# cslr_aif register map
Vendor: Texas Instruments
Registers are 32-bit, access per field, reset 0x0 unless marked. A register's access mark holds for its fields unless they carry their own. Offsets are as the file gives them; [hi:lo] are bit positions; {n}, {i} and the like mark numbered series; 'fields as' and 'values as' point back to an identical list.

## AIF (part 3 of 5) — High-speed interface for BTS antenna data
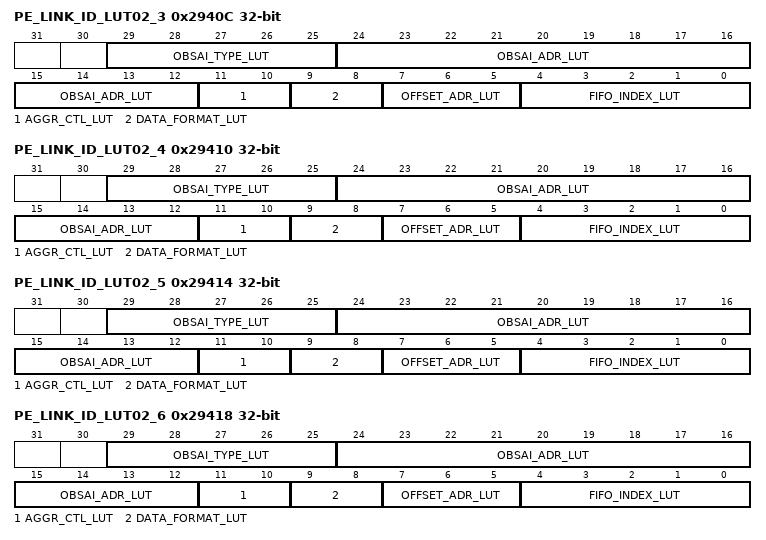
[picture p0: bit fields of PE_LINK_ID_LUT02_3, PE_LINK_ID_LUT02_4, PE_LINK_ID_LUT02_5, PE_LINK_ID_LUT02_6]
0x2940C PE_LINK_ID_LUT02_3 — Protocol Encoder Identity LUT part 0{PE_LINK_ID_LUT02}
  [29:25] OBSAI_TYPE_LUT rw — Bits [4:0]: OBSAI type, fixed per antenna carrier (circuit switched only)
  [24:12] OBSAI_ADR_LUT rw — Bits [12:0]: OBSAI address, fixed per antenna carrier (circuit switched only)
  [11:10] AGGR_CTL_LUT rw — Bits [1:0]: Aggregation control bits (assuming Tx_Rule passes)
    0=NOP (NOP (Ag still pulls from FIFO, but does not use read PE data bytes)); 1=INSERT; 2=ADD15_16 (Add 15/16bit); 3=ADD7_8 (Add 7/8bit)
  [9:8] DATA_FORMAT_LUT rw — Bits [1:0]: Internal Data format:
    0=DL_FMT (DL Format(only legal with burst of 4)); 1=UL_FMT (UL RSA Format(only legal for burst of 8)); 2=PIC_FMT (PIC MAI); 3=GEN_FMT (Generic Format)
  [7:5] OFFSET_ADR_LUT rw — Bits [2:0]: Circularly offsets reads from circuit switched RAM by n*4 chips. 8 chip orientated UL data disregard the LSB assuming it is zero. This offset is used to correct RAM alignment between streams different MOD32 offsets with one another. Allows chained DMA's to be more regular.
  [4:0] FIFO_INDEX_LUT rw — Bite [4:0]: pktsw FIFO Index[4:0]. Used to address fifo corresponding to this link.
0x29410 PE_LINK_ID_LUT02_4 — Protocol Encoder Identity LUT part 0{PE_LINK_ID_LUT02}
  fields as PE_LINK_ID_LUT02_3
0x29414 PE_LINK_ID_LUT02_5 — Protocol Encoder Identity LUT part 0{PE_LINK_ID_LUT02}
  fields as PE_LINK_ID_LUT02_3
0x29418 PE_LINK_ID_LUT02_6 — Protocol Encoder Identity LUT part 0{PE_LINK_ID_LUT02}
  fields as PE_LINK_ID_LUT02_3
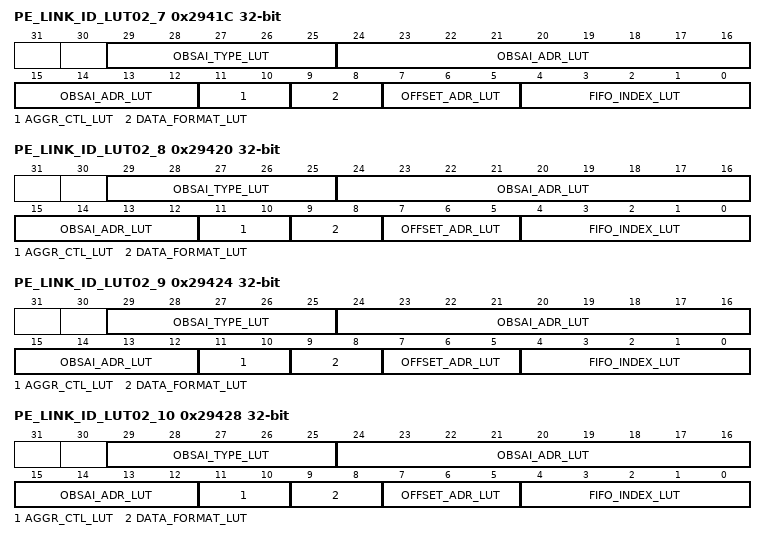
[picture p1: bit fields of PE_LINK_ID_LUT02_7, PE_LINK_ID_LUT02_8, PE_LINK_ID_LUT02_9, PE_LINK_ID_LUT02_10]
0x2941C PE_LINK_ID_LUT02_7 — Protocol Encoder Identity LUT part 0{PE_LINK_ID_LUT02}
  fields as PE_LINK_ID_LUT02_3
0x29420 PE_LINK_ID_LUT02_8 — Protocol Encoder Identity LUT part 0{PE_LINK_ID_LUT02}
  fields as PE_LINK_ID_LUT02_3
0x29424 PE_LINK_ID_LUT02_9 — Protocol Encoder Identity LUT part 0{PE_LINK_ID_LUT02}
  fields as PE_LINK_ID_LUT02_3
0x29428 PE_LINK_ID_LUT02_10 — Protocol Encoder Identity LUT part 0{PE_LINK_ID_LUT02}
  fields as PE_LINK_ID_LUT02_3
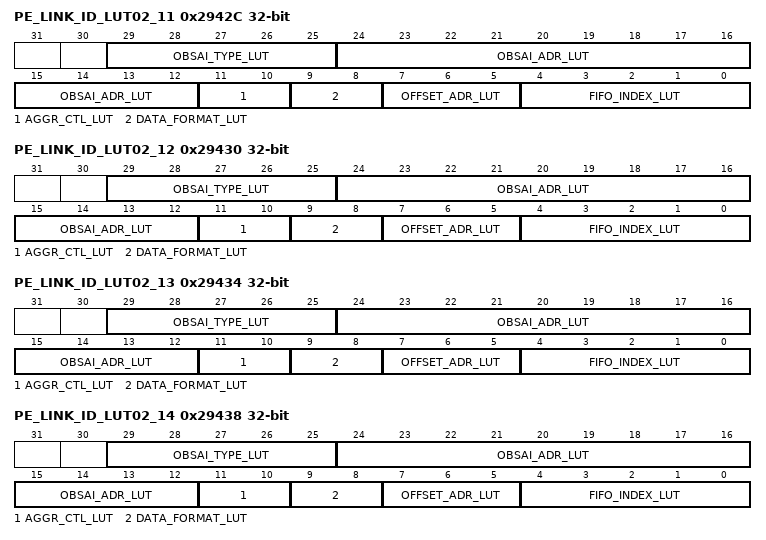
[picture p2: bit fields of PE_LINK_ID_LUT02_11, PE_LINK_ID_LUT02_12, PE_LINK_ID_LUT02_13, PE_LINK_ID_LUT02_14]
0x2942C PE_LINK_ID_LUT02_11 — Protocol Encoder Identity LUT part 0{PE_LINK_ID_LUT02}
  fields as PE_LINK_ID_LUT02_3
0x29430 PE_LINK_ID_LUT02_12 — Protocol Encoder Identity LUT part 0{PE_LINK_ID_LUT02}
  fields as PE_LINK_ID_LUT02_3
0x29434 PE_LINK_ID_LUT02_13 — Protocol Encoder Identity LUT part 0{PE_LINK_ID_LUT02}
  fields as PE_LINK_ID_LUT02_3
0x29438 PE_LINK_ID_LUT02_14 — Protocol Encoder Identity LUT part 0{PE_LINK_ID_LUT02}
  fields as PE_LINK_ID_LUT02_3
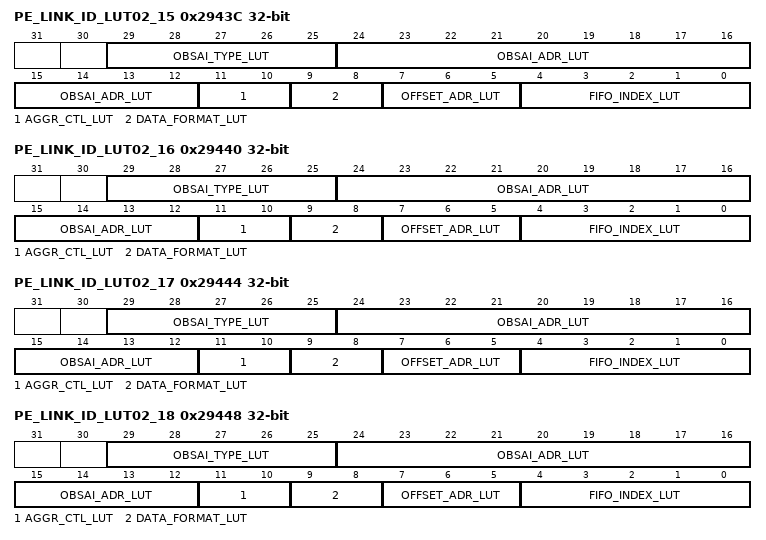
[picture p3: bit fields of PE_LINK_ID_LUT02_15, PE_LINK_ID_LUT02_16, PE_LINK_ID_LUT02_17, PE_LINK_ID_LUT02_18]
0x2943C PE_LINK_ID_LUT02_15 — Protocol Encoder Identity LUT part 0{PE_LINK_ID_LUT02}
  fields as PE_LINK_ID_LUT02_3
0x29440 PE_LINK_ID_LUT02_16 — Protocol Encoder Identity LUT part 0{PE_LINK_ID_LUT02}
  fields as PE_LINK_ID_LUT02_3
0x29444 PE_LINK_ID_LUT02_17 — Protocol Encoder Identity LUT part 0{PE_LINK_ID_LUT02}
  fields as PE_LINK_ID_LUT02_3
0x29448 PE_LINK_ID_LUT02_18 — Protocol Encoder Identity LUT part 0{PE_LINK_ID_LUT02}
  fields as PE_LINK_ID_LUT02_3
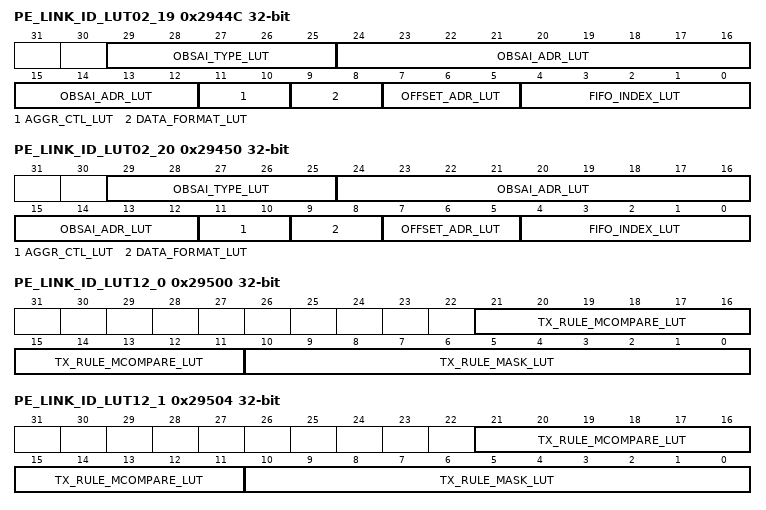
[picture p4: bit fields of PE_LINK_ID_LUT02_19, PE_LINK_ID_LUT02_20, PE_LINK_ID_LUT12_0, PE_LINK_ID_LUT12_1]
0x2944C PE_LINK_ID_LUT02_19 — Protocol Encoder Identity LUT part 0{PE_LINK_ID_LUT02}
  fields as PE_LINK_ID_LUT02_3
0x29450 PE_LINK_ID_LUT02_20 — Protocol Encoder Identity LUT part 0{PE_LINK_ID_LUT02}
  fields as PE_LINK_ID_LUT02_3
0x29500 PE_LINK_ID_LUT12_0 — Protocol Encoder Identity LUT part 1{PE_LINK_ID_LUT12}
  [21:11] TX_RULE_MCOMPARE_LUT rw — Bits [10:0]: Transmission rule compare bits. Field is bitwise XNOR with current counter value. Enabled results (see tx_rule_mask) are reduction AND giving a pass/fail of the transmission rule.
  [10:0] TX_RULE_MASK_LUT rw — Bits [10:0]: transmission rule mask. Indicates which counter bits should be compared. 0: indicates bit automatically passes compare 1: indicates counter bit should be compared with tx_rule_compare field.
0x29504 PE_LINK_ID_LUT12_1 — Protocol Encoder Identity LUT part 1{PE_LINK_ID_LUT12}
  fields as PE_LINK_ID_LUT12_0
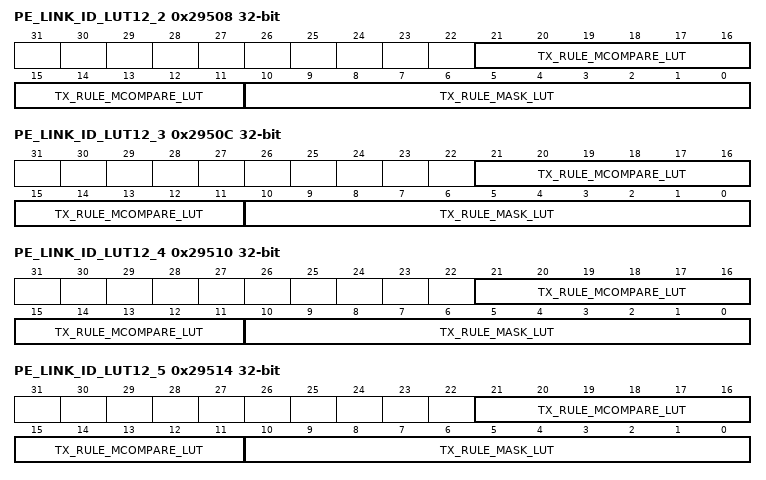
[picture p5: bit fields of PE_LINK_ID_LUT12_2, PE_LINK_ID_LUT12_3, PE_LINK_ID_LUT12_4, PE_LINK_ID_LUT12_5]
0x29508 PE_LINK_ID_LUT12_2 — Protocol Encoder Identity LUT part 1{PE_LINK_ID_LUT12}
  fields as PE_LINK_ID_LUT12_0
0x2950C PE_LINK_ID_LUT12_3 — Protocol Encoder Identity LUT part 1{PE_LINK_ID_LUT12}
  fields as PE_LINK_ID_LUT12_0
0x29510 PE_LINK_ID_LUT12_4 — Protocol Encoder Identity LUT part 1{PE_LINK_ID_LUT12}
  fields as PE_LINK_ID_LUT12_0
0x29514 PE_LINK_ID_LUT12_5 — Protocol Encoder Identity LUT part 1{PE_LINK_ID_LUT12}
  fields as PE_LINK_ID_LUT12_0
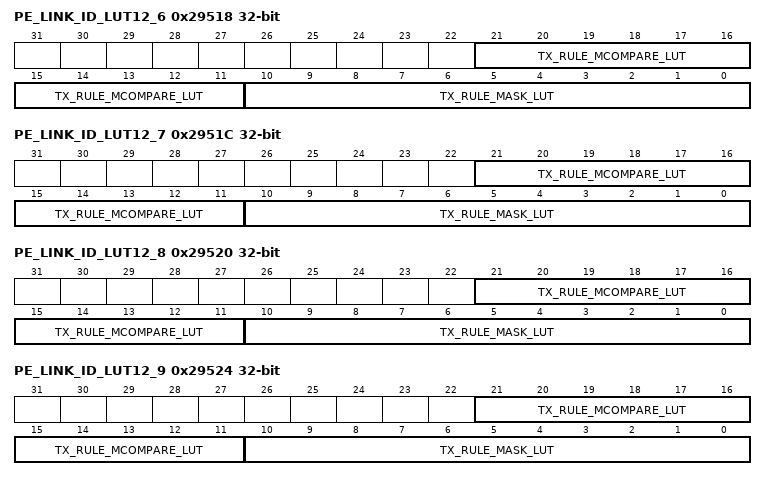
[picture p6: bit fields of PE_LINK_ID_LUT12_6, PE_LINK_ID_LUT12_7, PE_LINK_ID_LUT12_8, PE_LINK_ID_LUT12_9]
0x29518 PE_LINK_ID_LUT12_6 — Protocol Encoder Identity LUT part 1{PE_LINK_ID_LUT12}
  fields as PE_LINK_ID_LUT12_0
0x2951C PE_LINK_ID_LUT12_7 — Protocol Encoder Identity LUT part 1{PE_LINK_ID_LUT12}
  fields as PE_LINK_ID_LUT12_0
0x29520 PE_LINK_ID_LUT12_8 — Protocol Encoder Identity LUT part 1{PE_LINK_ID_LUT12}
  fields as PE_LINK_ID_LUT12_0
0x29524 PE_LINK_ID_LUT12_9 — Protocol Encoder Identity LUT part 1{PE_LINK_ID_LUT12}
  fields as PE_LINK_ID_LUT12_0
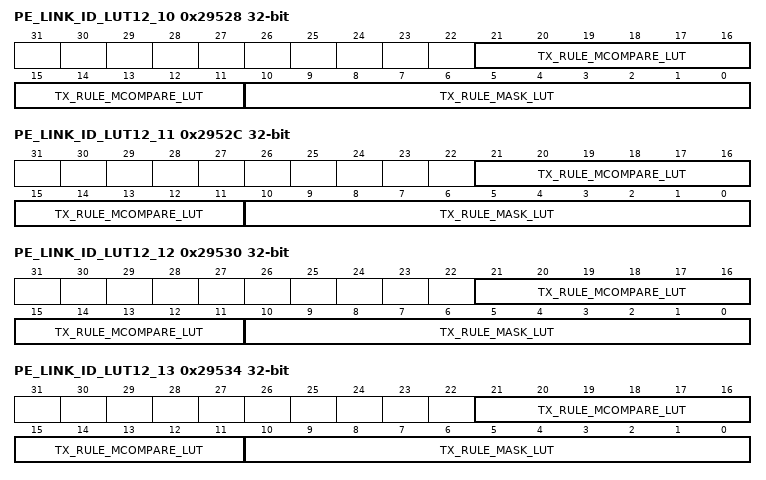
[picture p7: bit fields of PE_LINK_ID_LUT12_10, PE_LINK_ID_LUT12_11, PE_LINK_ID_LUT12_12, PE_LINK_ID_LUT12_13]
0x29528 PE_LINK_ID_LUT12_10 — Protocol Encoder Identity LUT part 1{PE_LINK_ID_LUT12}
  fields as PE_LINK_ID_LUT12_0
0x2952C PE_LINK_ID_LUT12_11 — Protocol Encoder Identity LUT part 1{PE_LINK_ID_LUT12}
  fields as PE_LINK_ID_LUT12_0
0x29530 PE_LINK_ID_LUT12_12 — Protocol Encoder Identity LUT part 1{PE_LINK_ID_LUT12}
  fields as PE_LINK_ID_LUT12_0
0x29534 PE_LINK_ID_LUT12_13 — Protocol Encoder Identity LUT part 1{PE_LINK_ID_LUT12}
  fields as PE_LINK_ID_LUT12_0
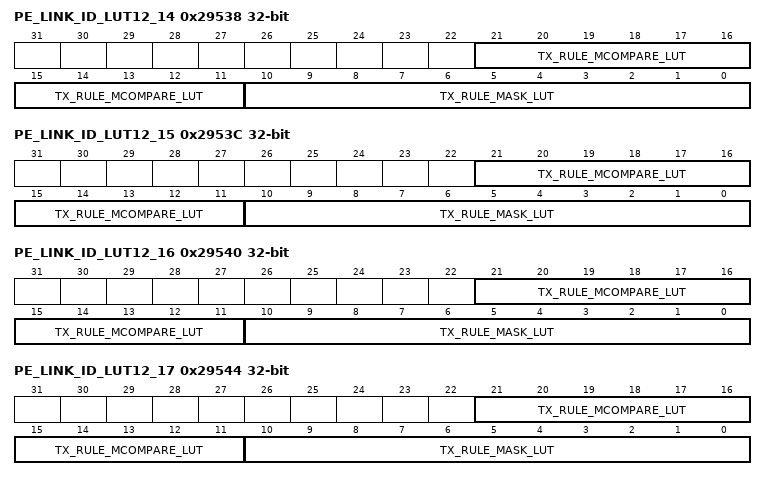
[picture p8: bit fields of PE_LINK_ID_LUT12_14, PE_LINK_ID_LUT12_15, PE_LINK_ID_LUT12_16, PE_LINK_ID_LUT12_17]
0x29538 PE_LINK_ID_LUT12_14 — Protocol Encoder Identity LUT part 1{PE_LINK_ID_LUT12}
  fields as PE_LINK_ID_LUT12_0
0x2953C PE_LINK_ID_LUT12_15 — Protocol Encoder Identity LUT part 1{PE_LINK_ID_LUT12}
  fields as PE_LINK_ID_LUT12_0
0x29540 PE_LINK_ID_LUT12_16 — Protocol Encoder Identity LUT part 1{PE_LINK_ID_LUT12}
  fields as PE_LINK_ID_LUT12_0
0x29544 PE_LINK_ID_LUT12_17 — Protocol Encoder Identity LUT part 1{PE_LINK_ID_LUT12}
  fields as PE_LINK_ID_LUT12_0
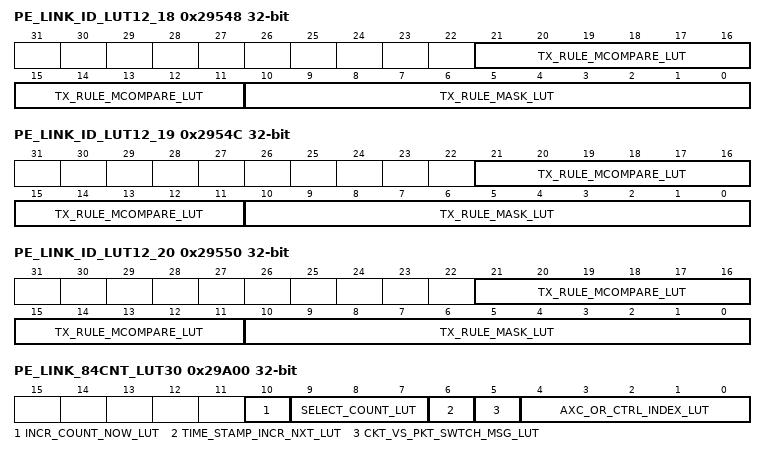
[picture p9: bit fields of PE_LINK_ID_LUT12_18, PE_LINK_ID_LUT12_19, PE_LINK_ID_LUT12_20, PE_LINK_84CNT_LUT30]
0x29548 PE_LINK_ID_LUT12_18 — Protocol Encoder Identity LUT part 1{PE_LINK_ID_LUT12}
  fields as PE_LINK_ID_LUT12_0
0x2954C PE_LINK_ID_LUT12_19 — Protocol Encoder Identity LUT part 1{PE_LINK_ID_LUT12}
  fields as PE_LINK_ID_LUT12_0
0x29550 PE_LINK_ID_LUT12_20 — Protocol Encoder Identity LUT part 1{PE_LINK_ID_LUT12}
  fields as PE_LINK_ID_LUT12_0
0x29A00 PE_LINK_84CNT_LUT30 — Protocol Encoder Link 84 Count LUT{PE_LINK_84CNT_LUT3}
  [10] INCR_COUNT_NOW_LUT rw — controls counter to increment, Incremented value is used for next operation (current operation uses current counter value)
    1=ICNR; 0=NO_INCR
  [9:7] SELECT_COUNT_LUT rw — Bits [2:0]: "0"-"3": Selects 4x Control Slot Counters or "4": 1x Data Slot Counter for Increment and for use with transmission rule
    {v}=CTRL{v} (v=0..3); 4=DATA
  [6] TIME_STAMP_INCR_NXT_LUT rw — Controls Time Stamp to increment, Incremented value is used for next message
  [5] CKT_VS_PKT_SWTCH_MSG_LUT rw — 0: circuit switched data
    0=PACKET; 1=CIRCUIT
  [4:0] AXC_OR_CTRL_INDEX_LUT rw — Bits [4:0]: Index for accessing the identity LUT.
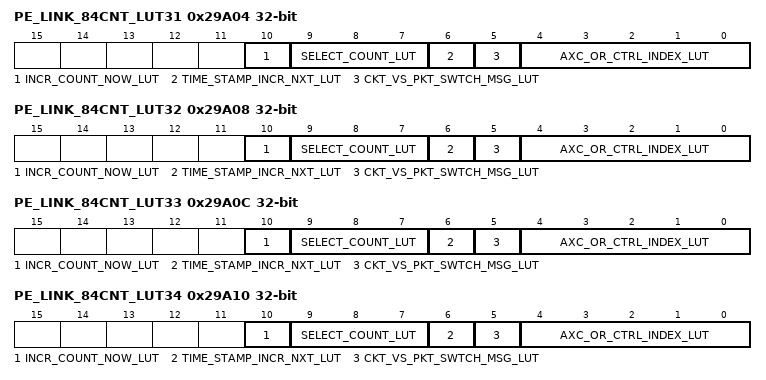
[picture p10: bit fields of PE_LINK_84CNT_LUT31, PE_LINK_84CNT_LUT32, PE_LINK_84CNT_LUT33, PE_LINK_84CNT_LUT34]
0x29A04 PE_LINK_84CNT_LUT31 — Protocol Encoder Link 84 Count LUT{PE_LINK_84CNT_LUT3}
  fields as PE_LINK_84CNT_LUT30
0x29A08 PE_LINK_84CNT_LUT32 — Protocol Encoder Link 84 Count LUT{PE_LINK_84CNT_LUT3}
  fields as PE_LINK_84CNT_LUT30
0x29A0C PE_LINK_84CNT_LUT33 — Protocol Encoder Link 84 Count LUT{PE_LINK_84CNT_LUT3}
  fields as PE_LINK_84CNT_LUT30
0x29A10 PE_LINK_84CNT_LUT34 — Protocol Encoder Link 84 Count LUT{PE_LINK_84CNT_LUT3}
  fields as PE_LINK_84CNT_LUT30
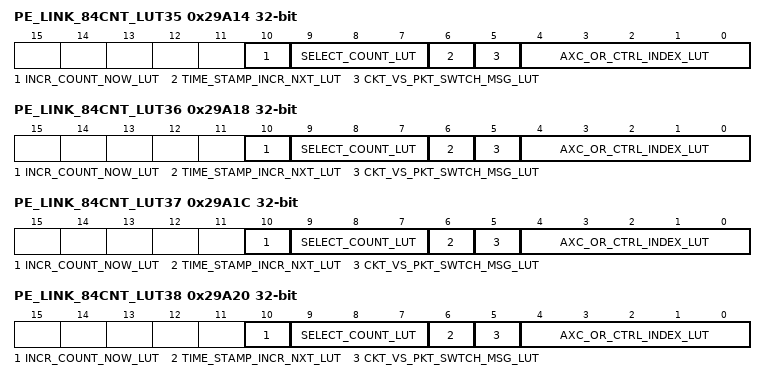
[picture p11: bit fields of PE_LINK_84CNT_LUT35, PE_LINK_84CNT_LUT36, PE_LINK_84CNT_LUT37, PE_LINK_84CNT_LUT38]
0x29A14 PE_LINK_84CNT_LUT35 — Protocol Encoder Link 84 Count LUT{PE_LINK_84CNT_LUT3}
  fields as PE_LINK_84CNT_LUT30
0x29A18 PE_LINK_84CNT_LUT36 — Protocol Encoder Link 84 Count LUT{PE_LINK_84CNT_LUT3}
  fields as PE_LINK_84CNT_LUT30
0x29A1C PE_LINK_84CNT_LUT37 — Protocol Encoder Link 84 Count LUT{PE_LINK_84CNT_LUT3}
  fields as PE_LINK_84CNT_LUT30
0x29A20 PE_LINK_84CNT_LUT38 — Protocol Encoder Link 84 Count LUT{PE_LINK_84CNT_LUT3}
  fields as PE_LINK_84CNT_LUT30
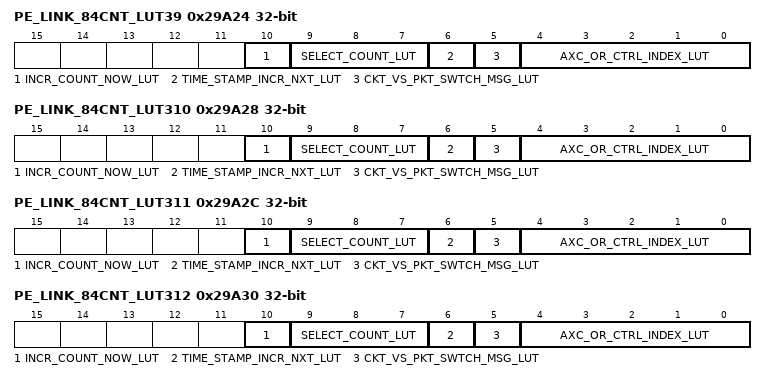
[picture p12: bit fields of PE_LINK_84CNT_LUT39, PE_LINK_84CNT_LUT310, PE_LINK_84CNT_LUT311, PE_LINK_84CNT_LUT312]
0x29A24 PE_LINK_84CNT_LUT39 — Protocol Encoder Link 84 Count LUT{PE_LINK_84CNT_LUT3}
  fields as PE_LINK_84CNT_LUT30
0x29A28 PE_LINK_84CNT_LUT310 — Protocol Encoder Link 84 Count LUT{PE_LINK_84CNT_LUT3}
  fields as PE_LINK_84CNT_LUT30
0x29A2C PE_LINK_84CNT_LUT311 — Protocol Encoder Link 84 Count LUT{PE_LINK_84CNT_LUT3}
  fields as PE_LINK_84CNT_LUT30
0x29A30 PE_LINK_84CNT_LUT312 — Protocol Encoder Link 84 Count LUT{PE_LINK_84CNT_LUT3}
  fields as PE_LINK_84CNT_LUT30
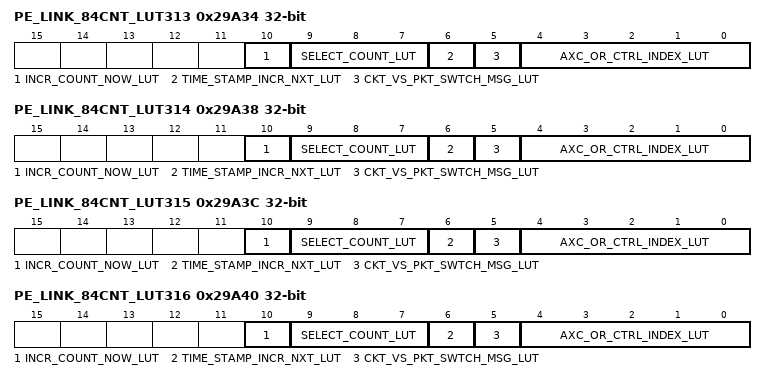
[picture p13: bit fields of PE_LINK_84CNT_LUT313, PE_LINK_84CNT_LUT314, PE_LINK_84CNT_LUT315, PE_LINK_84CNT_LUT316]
0x29A34 PE_LINK_84CNT_LUT313 — Protocol Encoder Link 84 Count LUT{PE_LINK_84CNT_LUT3}
  fields as PE_LINK_84CNT_LUT30
0x29A38 PE_LINK_84CNT_LUT314 — Protocol Encoder Link 84 Count LUT{PE_LINK_84CNT_LUT3}
  fields as PE_LINK_84CNT_LUT30
0x29A3C PE_LINK_84CNT_LUT315 — Protocol Encoder Link 84 Count LUT{PE_LINK_84CNT_LUT3}
  fields as PE_LINK_84CNT_LUT30
0x29A40 PE_LINK_84CNT_LUT316 — Protocol Encoder Link 84 Count LUT{PE_LINK_84CNT_LUT3}
  fields as PE_LINK_84CNT_LUT30
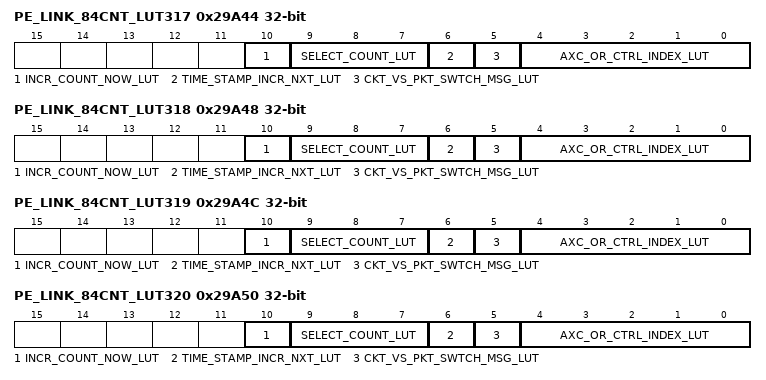
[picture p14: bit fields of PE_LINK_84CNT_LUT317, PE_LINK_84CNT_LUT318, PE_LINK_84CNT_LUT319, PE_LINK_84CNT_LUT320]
0x29A44 PE_LINK_84CNT_LUT317 — Protocol Encoder Link 84 Count LUT{PE_LINK_84CNT_LUT3}
  fields as PE_LINK_84CNT_LUT30
0x29A48 PE_LINK_84CNT_LUT318 — Protocol Encoder Link 84 Count LUT{PE_LINK_84CNT_LUT3}
  fields as PE_LINK_84CNT_LUT30
0x29A4C PE_LINK_84CNT_LUT319 — Protocol Encoder Link 84 Count LUT{PE_LINK_84CNT_LUT3}
  fields as PE_LINK_84CNT_LUT30
0x29A50 PE_LINK_84CNT_LUT320 — Protocol Encoder Link 84 Count LUT{PE_LINK_84CNT_LUT3}
  fields as PE_LINK_84CNT_LUT30
0x29A54 PE_LINK_84CNT_LUT321 — Protocol Encoder Link 84 Count LUT{PE_LINK_84CNT_LUT3}
  fields as PE_LINK_84CNT_LUT30
0x29A58 PE_LINK_84CNT_LUT322 — Protocol Encoder Link 84 Count LUT{PE_LINK_84CNT_LUT3}
  fields as PE_LINK_84CNT_LUT30
0x29A5C PE_LINK_84CNT_LUT323 — Protocol Encoder Link 84 Count LUT{PE_LINK_84CNT_LUT3}
  fields as PE_LINK_84CNT_LUT30
0x29A60 PE_LINK_84CNT_LUT324 — Protocol Encoder Link 84 Count LUT{PE_LINK_84CNT_LUT3}
  fields as PE_LINK_84CNT_LUT30
0x29A64 PE_LINK_84CNT_LUT325 — Protocol Encoder Link 84 Count LUT{PE_LINK_84CNT_LUT3}
  fields as PE_LINK_84CNT_LUT30
0x29A68 PE_LINK_84CNT_LUT326 — Protocol Encoder Link 84 Count LUT{PE_LINK_84CNT_LUT3}
  fields as PE_LINK_84CNT_LUT30
0x29A6C PE_LINK_84CNT_LUT327 — Protocol Encoder Link 84 Count LUT{PE_LINK_84CNT_LUT3}
  fields as PE_LINK_84CNT_LUT30
0x29A70 PE_LINK_84CNT_LUT328 — Protocol Encoder Link 84 Count LUT{PE_LINK_84CNT_LUT3}
  fields as PE_LINK_84CNT_LUT30
0x29A74 PE_LINK_84CNT_LUT329 — Protocol Encoder Link 84 Count LUT{PE_LINK_84CNT_LUT3}
  fields as PE_LINK_84CNT_LUT30
0x29A78 PE_LINK_84CNT_LUT330 — Protocol Encoder Link 84 Count LUT{PE_LINK_84CNT_LUT3}
  fields as PE_LINK_84CNT_LUT30
0x29A7C PE_LINK_84CNT_LUT331 — Protocol Encoder Link 84 Count LUT{PE_LINK_84CNT_LUT3}
  fields as PE_LINK_84CNT_LUT30
0x29A80 PE_LINK_84CNT_LUT332 — Protocol Encoder Link 84 Count LUT{PE_LINK_84CNT_LUT3}
  fields as PE_LINK_84CNT_LUT30
0x29A84 PE_LINK_84CNT_LUT333 — Protocol Encoder Link 84 Count LUT{PE_LINK_84CNT_LUT3}
  fields as PE_LINK_84CNT_LUT30
0x29A88 PE_LINK_84CNT_LUT334 — Protocol Encoder Link 84 Count LUT{PE_LINK_84CNT_LUT3}
  fields as PE_LINK_84CNT_LUT30
0x29A8C PE_LINK_84CNT_LUT335 — Protocol Encoder Link 84 Count LUT{PE_LINK_84CNT_LUT3}
  fields as PE_LINK_84CNT_LUT30
0x29A90 PE_LINK_84CNT_LUT336 — Protocol Encoder Link 84 Count LUT{PE_LINK_84CNT_LUT3}
  fields as PE_LINK_84CNT_LUT30
0x29A94 PE_LINK_84CNT_LUT337 — Protocol Encoder Link 84 Count LUT{PE_LINK_84CNT_LUT3}
  fields as PE_LINK_84CNT_LUT30
0x29A98 PE_LINK_84CNT_LUT338 — Protocol Encoder Link 84 Count LUT{PE_LINK_84CNT_LUT3}
  fields as PE_LINK_84CNT_LUT30
0x29A9C PE_LINK_84CNT_LUT339 — Protocol Encoder Link 84 Count LUT{PE_LINK_84CNT_LUT3}
  fields as PE_LINK_84CNT_LUT30
0x29AA0 PE_LINK_84CNT_LUT340 — Protocol Encoder Link 84 Count LUT{PE_LINK_84CNT_LUT3}
  fields as PE_LINK_84CNT_LUT30
0x29AA4 PE_LINK_84CNT_LUT341 — Protocol Encoder Link 84 Count LUT{PE_LINK_84CNT_LUT3}
  fields as PE_LINK_84CNT_LUT30
0x29AA8 PE_LINK_84CNT_LUT342 — Protocol Encoder Link 84 Count LUT{PE_LINK_84CNT_LUT3}
  fields as PE_LINK_84CNT_LUT30
0x29AAC PE_LINK_84CNT_LUT343 — Protocol Encoder Link 84 Count LUT{PE_LINK_84CNT_LUT3}
  fields as PE_LINK_84CNT_LUT30
0x29AB0 PE_LINK_84CNT_LUT344 — Protocol Encoder Link 84 Count LUT{PE_LINK_84CNT_LUT3}
  fields as PE_LINK_84CNT_LUT30
0x29AB4 PE_LINK_84CNT_LUT345 — Protocol Encoder Link 84 Count LUT{PE_LINK_84CNT_LUT3}
  fields as PE_LINK_84CNT_LUT30
0x29AB8 PE_LINK_84CNT_LUT346 — Protocol Encoder Link 84 Count LUT{PE_LINK_84CNT_LUT3}
  fields as PE_LINK_84CNT_LUT30
0x29ABC PE_LINK_84CNT_LUT347 — Protocol Encoder Link 84 Count LUT{PE_LINK_84CNT_LUT3}
  fields as PE_LINK_84CNT_LUT30
0x29AC0 PE_LINK_84CNT_LUT348 — Protocol Encoder Link 84 Count LUT{PE_LINK_84CNT_LUT3}
  fields as PE_LINK_84CNT_LUT30
0x29AC4 PE_LINK_84CNT_LUT349 — Protocol Encoder Link 84 Count LUT{PE_LINK_84CNT_LUT3}
  fields as PE_LINK_84CNT_LUT30
0x29AC8 PE_LINK_84CNT_LUT350 — Protocol Encoder Link 84 Count LUT{PE_LINK_84CNT_LUT3}
  fields as PE_LINK_84CNT_LUT30
0x29ACC PE_LINK_84CNT_LUT351 — Protocol Encoder Link 84 Count LUT{PE_LINK_84CNT_LUT3}
  fields as PE_LINK_84CNT_LUT30
0x29AD0 PE_LINK_84CNT_LUT352 — Protocol Encoder Link 84 Count LUT{PE_LINK_84CNT_LUT3}
  fields as PE_LINK_84CNT_LUT30
0x29AD4 PE_LINK_84CNT_LUT353 — Protocol Encoder Link 84 Count LUT{PE_LINK_84CNT_LUT3}
  fields as PE_LINK_84CNT_LUT30
0x29AD8 PE_LINK_84CNT_LUT354 — Protocol Encoder Link 84 Count LUT{PE_LINK_84CNT_LUT3}
  fields as PE_LINK_84CNT_LUT30
0x29ADC PE_LINK_84CNT_LUT355 — Protocol Encoder Link 84 Count LUT{PE_LINK_84CNT_LUT3}
  fields as PE_LINK_84CNT_LUT30
0x29AE0 PE_LINK_84CNT_LUT356 — Protocol Encoder Link 84 Count LUT{PE_LINK_84CNT_LUT3}
  fields as PE_LINK_84CNT_LUT30
0x29AE4 PE_LINK_84CNT_LUT357 — Protocol Encoder Link 84 Count LUT{PE_LINK_84CNT_LUT3}
  fields as PE_LINK_84CNT_LUT30
0x29AE8 PE_LINK_84CNT_LUT358 — Protocol Encoder Link 84 Count LUT{PE_LINK_84CNT_LUT3}
  fields as PE_LINK_84CNT_LUT30
0x29AEC PE_LINK_84CNT_LUT359 — Protocol Encoder Link 84 Count LUT{PE_LINK_84CNT_LUT3}
  fields as PE_LINK_84CNT_LUT30
0x29AF0 PE_LINK_84CNT_LUT360 — Protocol Encoder Link 84 Count LUT{PE_LINK_84CNT_LUT3}
  fields as PE_LINK_84CNT_LUT30
0x29AF4 PE_LINK_84CNT_LUT361 — Protocol Encoder Link 84 Count LUT{PE_LINK_84CNT_LUT3}
  fields as PE_LINK_84CNT_LUT30
0x29AF8 PE_LINK_84CNT_LUT362 — Protocol Encoder Link 84 Count LUT{PE_LINK_84CNT_LUT3}
  fields as PE_LINK_84CNT_LUT30
0x29AFC PE_LINK_84CNT_LUT363 — Protocol Encoder Link 84 Count LUT{PE_LINK_84CNT_LUT3}
  fields as PE_LINK_84CNT_LUT30
0x29B00 PE_LINK_84CNT_LUT364 — Protocol Encoder Link 84 Count LUT{PE_LINK_84CNT_LUT3}
  fields as PE_LINK_84CNT_LUT30
0x29B04 PE_LINK_84CNT_LUT365 — Protocol Encoder Link 84 Count LUT{PE_LINK_84CNT_LUT3}
  fields as PE_LINK_84CNT_LUT30
0x29B08 PE_LINK_84CNT_LUT366 — Protocol Encoder Link 84 Count LUT{PE_LINK_84CNT_LUT3}
  fields as PE_LINK_84CNT_LUT30
0x29B0C PE_LINK_84CNT_LUT367 — Protocol Encoder Link 84 Count LUT{PE_LINK_84CNT_LUT3}
  fields as PE_LINK_84CNT_LUT30
0x29B10 PE_LINK_84CNT_LUT368 — Protocol Encoder Link 84 Count LUT{PE_LINK_84CNT_LUT3}
  fields as PE_LINK_84CNT_LUT30
0x29B14 PE_LINK_84CNT_LUT369 — Protocol Encoder Link 84 Count LUT{PE_LINK_84CNT_LUT3}
  fields as PE_LINK_84CNT_LUT30
0x29B18 PE_LINK_84CNT_LUT370 — Protocol Encoder Link 84 Count LUT{PE_LINK_84CNT_LUT3}
  fields as PE_LINK_84CNT_LUT30
0x29B1C PE_LINK_84CNT_LUT371 — Protocol Encoder Link 84 Count LUT{PE_LINK_84CNT_LUT3}
  fields as PE_LINK_84CNT_LUT30
0x29B20 PE_LINK_84CNT_LUT372 — Protocol Encoder Link 84 Count LUT{PE_LINK_84CNT_LUT3}
  fields as PE_LINK_84CNT_LUT30
0x29B24 PE_LINK_84CNT_LUT373 — Protocol Encoder Link 84 Count LUT{PE_LINK_84CNT_LUT3}
  fields as PE_LINK_84CNT_LUT30
0x29B28 PE_LINK_84CNT_LUT374 — Protocol Encoder Link 84 Count LUT{PE_LINK_84CNT_LUT3}
  fields as PE_LINK_84CNT_LUT30
0x29B2C PE_LINK_84CNT_LUT375 — Protocol Encoder Link 84 Count LUT{PE_LINK_84CNT_LUT3}
  fields as PE_LINK_84CNT_LUT30
0x29B30 PE_LINK_84CNT_LUT376 — Protocol Encoder Link 84 Count LUT{PE_LINK_84CNT_LUT3}
  fields as PE_LINK_84CNT_LUT30
0x29B34 PE_LINK_84CNT_LUT377 — Protocol Encoder Link 84 Count LUT{PE_LINK_84CNT_LUT3}
  fields as PE_LINK_84CNT_LUT30
0x29B38 PE_LINK_84CNT_LUT378 — Protocol Encoder Link 84 Count LUT{PE_LINK_84CNT_LUT3}
  fields as PE_LINK_84CNT_LUT30
0x29B3C PE_LINK_84CNT_LUT379 — Protocol Encoder Link 84 Count LUT{PE_LINK_84CNT_LUT3}
  fields as PE_LINK_84CNT_LUT30
0x29B40 PE_LINK_84CNT_LUT380 — Protocol Encoder Link 84 Count LUT{PE_LINK_84CNT_LUT3}
  fields as PE_LINK_84CNT_LUT30
0x29B44 PE_LINK_84CNT_LUT381 — Protocol Encoder Link 84 Count LUT{PE_LINK_84CNT_LUT3}
  fields as PE_LINK_84CNT_LUT30
0x29B48 PE_LINK_84CNT_LUT382 — Protocol Encoder Link 84 Count LUT{PE_LINK_84CNT_LUT3}
  fields as PE_LINK_84CNT_LUT30
0x29B4C PE_LINK_84CNT_LUT383 — Protocol Encoder Link 84 Count LUT{PE_LINK_84CNT_LUT3}
  fields as PE_LINK_84CNT_LUT30
0x29C00 PE_LINK_ID_LUT03_0 — Protocol Encoder Identity LUT part 0{PE_LINK_ID_LUT03}
  fields as PE_LINK_ID_LUT02_3
0x29C04 PE_LINK_ID_LUT03_1 — Protocol Encoder Identity LUT part 0{PE_LINK_ID_LUT03}
  fields as PE_LINK_ID_LUT02_3
0x29C08 PE_LINK_ID_LUT03_2 — Protocol Encoder Identity LUT part 0{PE_LINK_ID_LUT03}
  fields as PE_LINK_ID_LUT02_3
0x29C0C PE_LINK_ID_LUT03_3 — Protocol Encoder Identity LUT part 0{PE_LINK_ID_LUT03}
  fields as PE_LINK_ID_LUT02_3
0x29C10 PE_LINK_ID_LUT03_4 — Protocol Encoder Identity LUT part 0{PE_LINK_ID_LUT03}
  fields as PE_LINK_ID_LUT02_3
0x29C14 PE_LINK_ID_LUT03_5 — Protocol Encoder Identity LUT part 0{PE_LINK_ID_LUT03}
  fields as PE_LINK_ID_LUT02_3
0x29C18 PE_LINK_ID_LUT03_6 — Protocol Encoder Identity LUT part 0{PE_LINK_ID_LUT03}
  fields as PE_LINK_ID_LUT02_3
0x29C1C PE_LINK_ID_LUT03_7 — Protocol Encoder Identity LUT part 0{PE_LINK_ID_LUT03}
  fields as PE_LINK_ID_LUT02_3
0x29C20 PE_LINK_ID_LUT03_8 — Protocol Encoder Identity LUT part 0{PE_LINK_ID_LUT03}
  fields as PE_LINK_ID_LUT02_3
0x29C24 PE_LINK_ID_LUT03_9 — Protocol Encoder Identity LUT part 0{PE_LINK_ID_LUT03}
  fields as PE_LINK_ID_LUT02_3
0x29C28 PE_LINK_ID_LUT03_10 — Protocol Encoder Identity LUT part 0{PE_LINK_ID_LUT03}
  fields as PE_LINK_ID_LUT02_3
0x29C2C PE_LINK_ID_LUT03_11 — Protocol Encoder Identity LUT part 0{PE_LINK_ID_LUT03}
  fields as PE_LINK_ID_LUT02_3
0x29C30 PE_LINK_ID_LUT03_12 — Protocol Encoder Identity LUT part 0{PE_LINK_ID_LUT03}
  fields as PE_LINK_ID_LUT02_3
0x29C34 PE_LINK_ID_LUT03_13 — Protocol Encoder Identity LUT part 0{PE_LINK_ID_LUT03}
  fields as PE_LINK_ID_LUT02_3
0x29C38 PE_LINK_ID_LUT03_14 — Protocol Encoder Identity LUT part 0{PE_LINK_ID_LUT03}
  fields as PE_LINK_ID_LUT02_3
0x29C3C PE_LINK_ID_LUT03_15 — Protocol Encoder Identity LUT part 0{PE_LINK_ID_LUT03}
  fields as PE_LINK_ID_LUT02_3
0x29C40 PE_LINK_ID_LUT03_16 — Protocol Encoder Identity LUT part 0{PE_LINK_ID_LUT03}
  fields as PE_LINK_ID_LUT02_3
0x29C44 PE_LINK_ID_LUT03_17 — Protocol Encoder Identity LUT part 0{PE_LINK_ID_LUT03}
  fields as PE_LINK_ID_LUT02_3
0x29C48 PE_LINK_ID_LUT03_18 — Protocol Encoder Identity LUT part 0{PE_LINK_ID_LUT03}
  fields as PE_LINK_ID_LUT02_3
0x29C4C PE_LINK_ID_LUT03_19 — Protocol Encoder Identity LUT part 0{PE_LINK_ID_LUT03}
  fields as PE_LINK_ID_LUT02_3
0x29C50 PE_LINK_ID_LUT03_20 — Protocol Encoder Identity LUT part 0{PE_LINK_ID_LUT03}
  fields as PE_LINK_ID_LUT02_3
0x29D00 PE_LINK_ID_LUT13_0 — Protocol Encoder Identity LUT part 1{PE_LINK_ID_LUT13}
  fields as PE_LINK_ID_LUT12_0
0x29D04 PE_LINK_ID_LUT13_1 — Protocol Encoder Identity LUT part 1{PE_LINK_ID_LUT13}
  fields as PE_LINK_ID_LUT12_0
0x29D08 PE_LINK_ID_LUT13_2 — Protocol Encoder Identity LUT part 1{PE_LINK_ID_LUT13}
  fields as PE_LINK_ID_LUT12_0
0x29D0C PE_LINK_ID_LUT13_3 — Protocol Encoder Identity LUT part 1{PE_LINK_ID_LUT13}
  fields as PE_LINK_ID_LUT12_0
0x29D10 PE_LINK_ID_LUT13_4 — Protocol Encoder Identity LUT part 1{PE_LINK_ID_LUT13}
  fields as PE_LINK_ID_LUT12_0
0x29D14 PE_LINK_ID_LUT13_5 — Protocol Encoder Identity LUT part 1{PE_LINK_ID_LUT13}
  fields as PE_LINK_ID_LUT12_0
0x29D18 PE_LINK_ID_LUT13_6 — Protocol Encoder Identity LUT part 1{PE_LINK_ID_LUT13}
  fields as PE_LINK_ID_LUT12_0
0x29D1C PE_LINK_ID_LUT13_7 — Protocol Encoder Identity LUT part 1{PE_LINK_ID_LUT13}
  fields as PE_LINK_ID_LUT12_0
0x29D20 PE_LINK_ID_LUT13_8 — Protocol Encoder Identity LUT part 1{PE_LINK_ID_LUT13}
  fields as PE_LINK_ID_LUT12_0
0x29D24 PE_LINK_ID_LUT13_9 — Protocol Encoder Identity LUT part 1{PE_LINK_ID_LUT13}
  fields as PE_LINK_ID_LUT12_0
0x29D28 PE_LINK_ID_LUT13_10 — Protocol Encoder Identity LUT part 1{PE_LINK_ID_LUT13}
  fields as PE_LINK_ID_LUT12_0
0x29D2C PE_LINK_ID_LUT13_11 — Protocol Encoder Identity LUT part 1{PE_LINK_ID_LUT13}
  fields as PE_LINK_ID_LUT12_0
0x29D30 PE_LINK_ID_LUT13_12 — Protocol Encoder Identity LUT part 1{PE_LINK_ID_LUT13}
  fields as PE_LINK_ID_LUT12_0
0x29D34 PE_LINK_ID_LUT13_13 — Protocol Encoder Identity LUT part 1{PE_LINK_ID_LUT13}
  fields as PE_LINK_ID_LUT12_0
0x29D38 PE_LINK_ID_LUT13_14 — Protocol Encoder Identity LUT part 1{PE_LINK_ID_LUT13}
  fields as PE_LINK_ID_LUT12_0
0x29D3C PE_LINK_ID_LUT13_15 — Protocol Encoder Identity LUT part 1{PE_LINK_ID_LUT13}
  fields as PE_LINK_ID_LUT12_0
0x29D40 PE_LINK_ID_LUT13_16 — Protocol Encoder Identity LUT part 1{PE_LINK_ID_LUT13}
  fields as PE_LINK_ID_LUT12_0
0x29D44 PE_LINK_ID_LUT13_17 — Protocol Encoder Identity LUT part 1{PE_LINK_ID_LUT13}
  fields as PE_LINK_ID_LUT12_0
0x29D48 PE_LINK_ID_LUT13_18 — Protocol Encoder Identity LUT part 1{PE_LINK_ID_LUT13}
  fields as PE_LINK_ID_LUT12_0
0x29D4C PE_LINK_ID_LUT13_19 — Protocol Encoder Identity LUT part 1{PE_LINK_ID_LUT13}
  fields as PE_LINK_ID_LUT12_0
0x29D50 PE_LINK_ID_LUT13_20 — Protocol Encoder Identity LUT part 1{PE_LINK_ID_LUT13}
  fields as PE_LINK_ID_LUT12_0
0x2A200 PE_LINK_84CNT_LUT40 — Protocol Encoder Link 84 Count LUT{PE_LINK_84CNT_LUT4}
  fields as PE_LINK_84CNT_LUT30
0x2A204 PE_LINK_84CNT_LUT41 — Protocol Encoder Link 84 Count LUT{PE_LINK_84CNT_LUT4}
  fields as PE_LINK_84CNT_LUT30
0x2A208 PE_LINK_84CNT_LUT42 — Protocol Encoder Link 84 Count LUT{PE_LINK_84CNT_LUT4}
  fields as PE_LINK_84CNT_LUT30
0x2A20C PE_LINK_84CNT_LUT43 — Protocol Encoder Link 84 Count LUT{PE_LINK_84CNT_LUT4}
  fields as PE_LINK_84CNT_LUT30
0x2A210 PE_LINK_84CNT_LUT44 — Protocol Encoder Link 84 Count LUT{PE_LINK_84CNT_LUT4}
  fields as PE_LINK_84CNT_LUT30
0x2A214 PE_LINK_84CNT_LUT45 — Protocol Encoder Link 84 Count LUT{PE_LINK_84CNT_LUT4}
  fields as PE_LINK_84CNT_LUT30
0x2A218 PE_LINK_84CNT_LUT46 — Protocol Encoder Link 84 Count LUT{PE_LINK_84CNT_LUT4}
  fields as PE_LINK_84CNT_LUT30
0x2A21C PE_LINK_84CNT_LUT47 — Protocol Encoder Link 84 Count LUT{PE_LINK_84CNT_LUT4}
  fields as PE_LINK_84CNT_LUT30
0x2A220 PE_LINK_84CNT_LUT48 — Protocol Encoder Link 84 Count LUT{PE_LINK_84CNT_LUT4}
  fields as PE_LINK_84CNT_LUT30
0x2A224 PE_LINK_84CNT_LUT49 — Protocol Encoder Link 84 Count LUT{PE_LINK_84CNT_LUT4}
  fields as PE_LINK_84CNT_LUT30
0x2A228 PE_LINK_84CNT_LUT410 — Protocol Encoder Link 84 Count LUT{PE_LINK_84CNT_LUT4}
  fields as PE_LINK_84CNT_LUT30
0x2A22C PE_LINK_84CNT_LUT411 — Protocol Encoder Link 84 Count LUT{PE_LINK_84CNT_LUT4}
  fields as PE_LINK_84CNT_LUT30
0x2A230 PE_LINK_84CNT_LUT412 — Protocol Encoder Link 84 Count LUT{PE_LINK_84CNT_LUT4}
  fields as PE_LINK_84CNT_LUT30
0x2A234 PE_LINK_84CNT_LUT413 — Protocol Encoder Link 84 Count LUT{PE_LINK_84CNT_LUT4}
  fields as PE_LINK_84CNT_LUT30
0x2A238 PE_LINK_84CNT_LUT414 — Protocol Encoder Link 84 Count LUT{PE_LINK_84CNT_LUT4}
  fields as PE_LINK_84CNT_LUT30
0x2A23C PE_LINK_84CNT_LUT415 — Protocol Encoder Link 84 Count LUT{PE_LINK_84CNT_LUT4}
  fields as PE_LINK_84CNT_LUT30
0x2A240 PE_LINK_84CNT_LUT416 — Protocol Encoder Link 84 Count LUT{PE_LINK_84CNT_LUT4}
  fields as PE_LINK_84CNT_LUT30
0x2A244 PE_LINK_84CNT_LUT417 — Protocol Encoder Link 84 Count LUT{PE_LINK_84CNT_LUT4}
  fields as PE_LINK_84CNT_LUT30
0x2A248 PE_LINK_84CNT_LUT418 — Protocol Encoder Link 84 Count LUT{PE_LINK_84CNT_LUT4}
  fields as PE_LINK_84CNT_LUT30
0x2A24C PE_LINK_84CNT_LUT419 — Protocol Encoder Link 84 Count LUT{PE_LINK_84CNT_LUT4}
  fields as PE_LINK_84CNT_LUT30
0x2A250 PE_LINK_84CNT_LUT420 — Protocol Encoder Link 84 Count LUT{PE_LINK_84CNT_LUT4}
  fields as PE_LINK_84CNT_LUT30
0x2A254 PE_LINK_84CNT_LUT421 — Protocol Encoder Link 84 Count LUT{PE_LINK_84CNT_LUT4}
  fields as PE_LINK_84CNT_LUT30
0x2A258 PE_LINK_84CNT_LUT422 — Protocol Encoder Link 84 Count LUT{PE_LINK_84CNT_LUT4}
  fields as PE_LINK_84CNT_LUT30
0x2A25C PE_LINK_84CNT_LUT423 — Protocol Encoder Link 84 Count LUT{PE_LINK_84CNT_LUT4}
  fields as PE_LINK_84CNT_LUT30
0x2A260 PE_LINK_84CNT_LUT424 — Protocol Encoder Link 84 Count LUT{PE_LINK_84CNT_LUT4}
  fields as PE_LINK_84CNT_LUT30
0x2A264 PE_LINK_84CNT_LUT425 — Protocol Encoder Link 84 Count LUT{PE_LINK_84CNT_LUT4}
  fields as PE_LINK_84CNT_LUT30
0x2A268 PE_LINK_84CNT_LUT426 — Protocol Encoder Link 84 Count LUT{PE_LINK_84CNT_LUT4}
  fields as PE_LINK_84CNT_LUT30
0x2A26C PE_LINK_84CNT_LUT427 — Protocol Encoder Link 84 Count LUT{PE_LINK_84CNT_LUT4}
  fields as PE_LINK_84CNT_LUT30
0x2A270 PE_LINK_84CNT_LUT428 — Protocol Encoder Link 84 Count LUT{PE_LINK_84CNT_LUT4}
  fields as PE_LINK_84CNT_LUT30
0x2A274 PE_LINK_84CNT_LUT429 — Protocol Encoder Link 84 Count LUT{PE_LINK_84CNT_LUT4}
  fields as PE_LINK_84CNT_LUT30
0x2A278 PE_LINK_84CNT_LUT430 — Protocol Encoder Link 84 Count LUT{PE_LINK_84CNT_LUT4}
  fields as PE_LINK_84CNT_LUT30
0x2A27C PE_LINK_84CNT_LUT431 — Protocol Encoder Link 84 Count LUT{PE_LINK_84CNT_LUT4}
  fields as PE_LINK_84CNT_LUT30
0x2A280 PE_LINK_84CNT_LUT432 — Protocol Encoder Link 84 Count LUT{PE_LINK_84CNT_LUT4}
  fields as PE_LINK_84CNT_LUT30
0x2A284 PE_LINK_84CNT_LUT433 — Protocol Encoder Link 84 Count LUT{PE_LINK_84CNT_LUT4}
  fields as PE_LINK_84CNT_LUT30
0x2A288 PE_LINK_84CNT_LUT434 — Protocol Encoder Link 84 Count LUT{PE_LINK_84CNT_LUT4}
  fields as PE_LINK_84CNT_LUT30
0x2A28C PE_LINK_84CNT_LUT435 — Protocol Encoder Link 84 Count LUT{PE_LINK_84CNT_LUT4}
  fields as PE_LINK_84CNT_LUT30
0x2A290 PE_LINK_84CNT_LUT436 — Protocol Encoder Link 84 Count LUT{PE_LINK_84CNT_LUT4}
  fields as PE_LINK_84CNT_LUT30
0x2A294 PE_LINK_84CNT_LUT437 — Protocol Encoder Link 84 Count LUT{PE_LINK_84CNT_LUT4}
  fields as PE_LINK_84CNT_LUT30
0x2A298 PE_LINK_84CNT_LUT438 — Protocol Encoder Link 84 Count LUT{PE_LINK_84CNT_LUT4}
  fields as PE_LINK_84CNT_LUT30
0x2A29C PE_LINK_84CNT_LUT439 — Protocol Encoder Link 84 Count LUT{PE_LINK_84CNT_LUT4}
  fields as PE_LINK_84CNT_LUT30
0x2A2A0 PE_LINK_84CNT_LUT440 — Protocol Encoder Link 84 Count LUT{PE_LINK_84CNT_LUT4}
  fields as PE_LINK_84CNT_LUT30
0x2A2A4 PE_LINK_84CNT_LUT441 — Protocol Encoder Link 84 Count LUT{PE_LINK_84CNT_LUT4}
  fields as PE_LINK_84CNT_LUT30
0x2A2A8 PE_LINK_84CNT_LUT442 — Protocol Encoder Link 84 Count LUT{PE_LINK_84CNT_LUT4}
  fields as PE_LINK_84CNT_LUT30
0x2A2AC PE_LINK_84CNT_LUT443 — Protocol Encoder Link 84 Count LUT{PE_LINK_84CNT_LUT4}
  fields as PE_LINK_84CNT_LUT30
0x2A2B0 PE_LINK_84CNT_LUT444 — Protocol Encoder Link 84 Count LUT{PE_LINK_84CNT_LUT4}
  fields as PE_LINK_84CNT_LUT30
0x2A2B4 PE_LINK_84CNT_LUT445 — Protocol Encoder Link 84 Count LUT{PE_LINK_84CNT_LUT4}
  fields as PE_LINK_84CNT_LUT30
0x2A2B8 PE_LINK_84CNT_LUT446 — Protocol Encoder Link 84 Count LUT{PE_LINK_84CNT_LUT4}
  fields as PE_LINK_84CNT_LUT30
0x2A2BC PE_LINK_84CNT_LUT447 — Protocol Encoder Link 84 Count LUT{PE_LINK_84CNT_LUT4}
  fields as PE_LINK_84CNT_LUT30
0x2A2C0 PE_LINK_84CNT_LUT448 — Protocol Encoder Link 84 Count LUT{PE_LINK_84CNT_LUT4}
  fields as PE_LINK_84CNT_LUT30
0x2A2C4 PE_LINK_84CNT_LUT449 — Protocol Encoder Link 84 Count LUT{PE_LINK_84CNT_LUT4}
  fields as PE_LINK_84CNT_LUT30
0x2A2C8 PE_LINK_84CNT_LUT450 — Protocol Encoder Link 84 Count LUT{PE_LINK_84CNT_LUT4}
  fields as PE_LINK_84CNT_LUT30
0x2A2CC PE_LINK_84CNT_LUT451 — Protocol Encoder Link 84 Count LUT{PE_LINK_84CNT_LUT4}
  fields as PE_LINK_84CNT_LUT30
0x2A2D0 PE_LINK_84CNT_LUT452 — Protocol Encoder Link 84 Count LUT{PE_LINK_84CNT_LUT4}
  fields as PE_LINK_84CNT_LUT30
0x2A2D4 PE_LINK_84CNT_LUT453 — Protocol Encoder Link 84 Count LUT{PE_LINK_84CNT_LUT4}
  fields as PE_LINK_84CNT_LUT30
0x2A2D8 PE_LINK_84CNT_LUT454 — Protocol Encoder Link 84 Count LUT{PE_LINK_84CNT_LUT4}
  fields as PE_LINK_84CNT_LUT30
0x2A2DC PE_LINK_84CNT_LUT455 — Protocol Encoder Link 84 Count LUT{PE_LINK_84CNT_LUT4}
  fields as PE_LINK_84CNT_LUT30
0x2A2E0 PE_LINK_84CNT_LUT456 — Protocol Encoder Link 84 Count LUT{PE_LINK_84CNT_LUT4}
  fields as PE_LINK_84CNT_LUT30
0x2A2E4 PE_LINK_84CNT_LUT457 — Protocol Encoder Link 84 Count LUT{PE_LINK_84CNT_LUT4}
  fields as PE_LINK_84CNT_LUT30
0x2A2E8 PE_LINK_84CNT_LUT458 — Protocol Encoder Link 84 Count LUT{PE_LINK_84CNT_LUT4}
  fields as PE_LINK_84CNT_LUT30
0x2A2EC PE_LINK_84CNT_LUT459 — Protocol Encoder Link 84 Count LUT{PE_LINK_84CNT_LUT4}
  fields as PE_LINK_84CNT_LUT30
0x2A2F0 PE_LINK_84CNT_LUT460 — Protocol Encoder Link 84 Count LUT{PE_LINK_84CNT_LUT4}
  fields as PE_LINK_84CNT_LUT30
0x2A2F4 PE_LINK_84CNT_LUT461 — Protocol Encoder Link 84 Count LUT{PE_LINK_84CNT_LUT4}
  fields as PE_LINK_84CNT_LUT30
0x2A2F8 PE_LINK_84CNT_LUT462 — Protocol Encoder Link 84 Count LUT{PE_LINK_84CNT_LUT4}
  fields as PE_LINK_84CNT_LUT30
0x2A2FC PE_LINK_84CNT_LUT463 — Protocol Encoder Link 84 Count LUT{PE_LINK_84CNT_LUT4}
  fields as PE_LINK_84CNT_LUT30
0x2A300 PE_LINK_84CNT_LUT464 — Protocol Encoder Link 84 Count LUT{PE_LINK_84CNT_LUT4}
  fields as PE_LINK_84CNT_LUT30
0x2A304 PE_LINK_84CNT_LUT465 — Protocol Encoder Link 84 Count LUT{PE_LINK_84CNT_LUT4}
  fields as PE_LINK_84CNT_LUT30
0x2A308 PE_LINK_84CNT_LUT466 — Protocol Encoder Link 84 Count LUT{PE_LINK_84CNT_LUT4}
  fields as PE_LINK_84CNT_LUT30
0x2A30C PE_LINK_84CNT_LUT467 — Protocol Encoder Link 84 Count LUT{PE_LINK_84CNT_LUT4}
  fields as PE_LINK_84CNT_LUT30
0x2A310 PE_LINK_84CNT_LUT468 — Protocol Encoder Link 84 Count LUT{PE_LINK_84CNT_LUT4}
  fields as PE_LINK_84CNT_LUT30
0x2A314 PE_LINK_84CNT_LUT469 — Protocol Encoder Link 84 Count LUT{PE_LINK_84CNT_LUT4}
  fields as PE_LINK_84CNT_LUT30
0x2A318 PE_LINK_84CNT_LUT470 — Protocol Encoder Link 84 Count LUT{PE_LINK_84CNT_LUT4}
  fields as PE_LINK_84CNT_LUT30
0x2A31C PE_LINK_84CNT_LUT471 — Protocol Encoder Link 84 Count LUT{PE_LINK_84CNT_LUT4}
  fields as PE_LINK_84CNT_LUT30
0x2A320 PE_LINK_84CNT_LUT472 — Protocol Encoder Link 84 Count LUT{PE_LINK_84CNT_LUT4}
  fields as PE_LINK_84CNT_LUT30
0x2A324 PE_LINK_84CNT_LUT473 — Protocol Encoder Link 84 Count LUT{PE_LINK_84CNT_LUT4}
  fields as PE_LINK_84CNT_LUT30
0x2A328 PE_LINK_84CNT_LUT474 — Protocol Encoder Link 84 Count LUT{PE_LINK_84CNT_LUT4}
  fields as PE_LINK_84CNT_LUT30
0x2A32C PE_LINK_84CNT_LUT475 — Protocol Encoder Link 84 Count LUT{PE_LINK_84CNT_LUT4}
  fields as PE_LINK_84CNT_LUT30
0x2A330 PE_LINK_84CNT_LUT476 — Protocol Encoder Link 84 Count LUT{PE_LINK_84CNT_LUT4}
  fields as PE_LINK_84CNT_LUT30
0x2A334 PE_LINK_84CNT_LUT477 — Protocol Encoder Link 84 Count LUT{PE_LINK_84CNT_LUT4}
  fields as PE_LINK_84CNT_LUT30
0x2A338 PE_LINK_84CNT_LUT478 — Protocol Encoder Link 84 Count LUT{PE_LINK_84CNT_LUT4}
  fields as PE_LINK_84CNT_LUT30
0x2A33C PE_LINK_84CNT_LUT479 — Protocol Encoder Link 84 Count LUT{PE_LINK_84CNT_LUT4}
  fields as PE_LINK_84CNT_LUT30
0x2A340 PE_LINK_84CNT_LUT480 — Protocol Encoder Link 84 Count LUT{PE_LINK_84CNT_LUT4}
  fields as PE_LINK_84CNT_LUT30
0x2A344 PE_LINK_84CNT_LUT481 — Protocol Encoder Link 84 Count LUT{PE_LINK_84CNT_LUT4}
  fields as PE_LINK_84CNT_LUT30
0x2A348 PE_LINK_84CNT_LUT482 — Protocol Encoder Link 84 Count LUT{PE_LINK_84CNT_LUT4}
  fields as PE_LINK_84CNT_LUT30
0x2A34C PE_LINK_84CNT_LUT483 — Protocol Encoder Link 84 Count LUT{PE_LINK_84CNT_LUT4}
  fields as PE_LINK_84CNT_LUT30
0x2A400 PE_LINK_ID_LUT04_0 — Protocol Encoder Identity LUT part 0{PE_LINK_ID_LUT04}
  fields as PE_LINK_ID_LUT02_3
0x2A404 PE_LINK_ID_LUT04_1 — Protocol Encoder Identity LUT part 0{PE_LINK_ID_LUT04}
  fields as PE_LINK_ID_LUT02_3
0x2A408 PE_LINK_ID_LUT04_2 — Protocol Encoder Identity LUT part 0{PE_LINK_ID_LUT04}
  fields as PE_LINK_ID_LUT02_3
0x2A40C PE_LINK_ID_LUT04_3 — Protocol Encoder Identity LUT part 0{PE_LINK_ID_LUT04}
  fields as PE_LINK_ID_LUT02_3
0x2A410 PE_LINK_ID_LUT04_4 — Protocol Encoder Identity LUT part 0{PE_LINK_ID_LUT04}
  fields as PE_LINK_ID_LUT02_3
0x2A414 PE_LINK_ID_LUT04_5 — Protocol Encoder Identity LUT part 0{PE_LINK_ID_LUT04}
  fields as PE_LINK_ID_LUT02_3
0x2A418 PE_LINK_ID_LUT04_6 — Protocol Encoder Identity LUT part 0{PE_LINK_ID_LUT04}
  fields as PE_LINK_ID_LUT02_3
0x2A41C PE_LINK_ID_LUT04_7 — Protocol Encoder Identity LUT part 0{PE_LINK_ID_LUT04}
  fields as PE_LINK_ID_LUT02_3
0x2A420 PE_LINK_ID_LUT04_8 — Protocol Encoder Identity LUT part 0{PE_LINK_ID_LUT04}
  fields as PE_LINK_ID_LUT02_3
0x2A424 PE_LINK_ID_LUT04_9 — Protocol Encoder Identity LUT part 0{PE_LINK_ID_LUT04}
  fields as PE_LINK_ID_LUT02_3
0x2A428 PE_LINK_ID_LUT04_10 — Protocol Encoder Identity LUT part 0{PE_LINK_ID_LUT04}
  fields as PE_LINK_ID_LUT02_3
0x2A42C PE_LINK_ID_LUT04_11 — Protocol Encoder Identity LUT part 0{PE_LINK_ID_LUT04}
  fields as PE_LINK_ID_LUT02_3
0x2A430 PE_LINK_ID_LUT04_12 — Protocol Encoder Identity LUT part 0{PE_LINK_ID_LUT04}
  fields as PE_LINK_ID_LUT02_3
0x2A434 PE_LINK_ID_LUT04_13 — Protocol Encoder Identity LUT part 0{PE_LINK_ID_LUT04}
  fields as PE_LINK_ID_LUT02_3
0x2A438 PE_LINK_ID_LUT04_14 — Protocol Encoder Identity LUT part 0{PE_LINK_ID_LUT04}
  fields as PE_LINK_ID_LUT02_3
0x2A43C PE_LINK_ID_LUT04_15 — Protocol Encoder Identity LUT part 0{PE_LINK_ID_LUT04}
  fields as PE_LINK_ID_LUT02_3
0x2A440 PE_LINK_ID_LUT04_16 — Protocol Encoder Identity LUT part 0{PE_LINK_ID_LUT04}
  fields as PE_LINK_ID_LUT02_3
0x2A444 PE_LINK_ID_LUT04_17 — Protocol Encoder Identity LUT part 0{PE_LINK_ID_LUT04}
  fields as PE_LINK_ID_LUT02_3
0x2A448 PE_LINK_ID_LUT04_18 — Protocol Encoder Identity LUT part 0{PE_LINK_ID_LUT04}
  fields as PE_LINK_ID_LUT02_3
0x2A44C PE_LINK_ID_LUT04_19 — Protocol Encoder Identity LUT part 0{PE_LINK_ID_LUT04}
  fields as PE_LINK_ID_LUT02_3
0x2A450 PE_LINK_ID_LUT04_20 — Protocol Encoder Identity LUT part 0{PE_LINK_ID_LUT04}
  fields as PE_LINK_ID_LUT02_3
0x2A500 PE_LINK_ID_LUT14_0 — Protocol Encoder Identity LUT part 1{PE_LINK_ID_LUT14}
  fields as PE_LINK_ID_LUT12_0
0x2A504 PE_LINK_ID_LUT14_1 — Protocol Encoder Identity LUT part 1{PE_LINK_ID_LUT14}
  fields as PE_LINK_ID_LUT12_0
0x2A508 PE_LINK_ID_LUT14_2 — Protocol Encoder Identity LUT part 1{PE_LINK_ID_LUT14}
  fields as PE_LINK_ID_LUT12_0
0x2A50C PE_LINK_ID_LUT14_3 — Protocol Encoder Identity LUT part 1{PE_LINK_ID_LUT14}
  fields as PE_LINK_ID_LUT12_0
0x2A510 PE_LINK_ID_LUT14_4 — Protocol Encoder Identity LUT part 1{PE_LINK_ID_LUT14}
  fields as PE_LINK_ID_LUT12_0
0x2A514 PE_LINK_ID_LUT14_5 — Protocol Encoder Identity LUT part 1{PE_LINK_ID_LUT14}
  fields as PE_LINK_ID_LUT12_0
0x2A518 PE_LINK_ID_LUT14_6 — Protocol Encoder Identity LUT part 1{PE_LINK_ID_LUT14}
  fields as PE_LINK_ID_LUT12_0
0x2A51C PE_LINK_ID_LUT14_7 — Protocol Encoder Identity LUT part 1{PE_LINK_ID_LUT14}
  fields as PE_LINK_ID_LUT12_0
0x2A520 PE_LINK_ID_LUT14_8 — Protocol Encoder Identity LUT part 1{PE_LINK_ID_LUT14}
  fields as PE_LINK_ID_LUT12_0
0x2A524 PE_LINK_ID_LUT14_9 — Protocol Encoder Identity LUT part 1{PE_LINK_ID_LUT14}
  fields as PE_LINK_ID_LUT12_0
0x2A528 PE_LINK_ID_LUT14_10 — Protocol Encoder Identity LUT part 1{PE_LINK_ID_LUT14}
  fields as PE_LINK_ID_LUT12_0
0x2A52C PE_LINK_ID_LUT14_11 — Protocol Encoder Identity LUT part 1{PE_LINK_ID_LUT14}
  fields as PE_LINK_ID_LUT12_0
0x2A530 PE_LINK_ID_LUT14_12 — Protocol Encoder Identity LUT part 1{PE_LINK_ID_LUT14}
  fields as PE_LINK_ID_LUT12_0
0x2A534 PE_LINK_ID_LUT14_13 — Protocol Encoder Identity LUT part 1{PE_LINK_ID_LUT14}
  fields as PE_LINK_ID_LUT12_0
0x2A538 PE_LINK_ID_LUT14_14 — Protocol Encoder Identity LUT part 1{PE_LINK_ID_LUT14}
  fields as PE_LINK_ID_LUT12_0
0x2A53C PE_LINK_ID_LUT14_15 — Protocol Encoder Identity LUT part 1{PE_LINK_ID_LUT14}
  fields as PE_LINK_ID_LUT12_0
0x2A540 PE_LINK_ID_LUT14_16 — Protocol Encoder Identity LUT part 1{PE_LINK_ID_LUT14}
  fields as PE_LINK_ID_LUT12_0
0x2A544 PE_LINK_ID_LUT14_17 — Protocol Encoder Identity LUT part 1{PE_LINK_ID_LUT14}
  fields as PE_LINK_ID_LUT12_0
0x2A548 PE_LINK_ID_LUT14_18 — Protocol Encoder Identity LUT part 1{PE_LINK_ID_LUT14}
  fields as PE_LINK_ID_LUT12_0
0x2A54C PE_LINK_ID_LUT14_19 — Protocol Encoder Identity LUT part 1{PE_LINK_ID_LUT14}
  fields as PE_LINK_ID_LUT12_0
0x2A550 PE_LINK_ID_LUT14_20 — Protocol Encoder Identity LUT part 1{PE_LINK_ID_LUT14}
  fields as PE_LINK_ID_LUT12_0
0x2AA00 PE_LINK_84CNT_LUT50 — Protocol Encoder Link 84 Count LUT{PE_LINK_84CNT_LUT5}
  fields as PE_LINK_84CNT_LUT30
0x2AA04 PE_LINK_84CNT_LUT51 — Protocol Encoder Link 84 Count LUT{PE_LINK_84CNT_LUT5}
  fields as PE_LINK_84CNT_LUT30
0x2AA08 PE_LINK_84CNT_LUT52 — Protocol Encoder Link 84 Count LUT{PE_LINK_84CNT_LUT5}
  fields as PE_LINK_84CNT_LUT30
0x2AA0C PE_LINK_84CNT_LUT53 — Protocol Encoder Link 84 Count LUT{PE_LINK_84CNT_LUT5}
  fields as PE_LINK_84CNT_LUT30
0x2AA10 PE_LINK_84CNT_LUT54 — Protocol Encoder Link 84 Count LUT{PE_LINK_84CNT_LUT5}
  fields as PE_LINK_84CNT_LUT30
0x2AA14 PE_LINK_84CNT_LUT55 — Protocol Encoder Link 84 Count LUT{PE_LINK_84CNT_LUT5}
  fields as PE_LINK_84CNT_LUT30
0x2AA18 PE_LINK_84CNT_LUT56 — Protocol Encoder Link 84 Count LUT{PE_LINK_84CNT_LUT5}
  fields as PE_LINK_84CNT_LUT30
0x2AA1C PE_LINK_84CNT_LUT57 — Protocol Encoder Link 84 Count LUT{PE_LINK_84CNT_LUT5}
  fields as PE_LINK_84CNT_LUT30
0x2AA20 PE_LINK_84CNT_LUT58 — Protocol Encoder Link 84 Count LUT{PE_LINK_84CNT_LUT5}
  fields as PE_LINK_84CNT_LUT30
0x2AA24 PE_LINK_84CNT_LUT59 — Protocol Encoder Link 84 Count LUT{PE_LINK_84CNT_LUT5}
  fields as PE_LINK_84CNT_LUT30
0x2AA28 PE_LINK_84CNT_LUT510 — Protocol Encoder Link 84 Count LUT{PE_LINK_84CNT_LUT5}
  fields as PE_LINK_84CNT_LUT30
0x2AA2C PE_LINK_84CNT_LUT511 — Protocol Encoder Link 84 Count LUT{PE_LINK_84CNT_LUT5}
  fields as PE_LINK_84CNT_LUT30
0x2AA30 PE_LINK_84CNT_LUT512 — Protocol Encoder Link 84 Count LUT{PE_LINK_84CNT_LUT5}
  fields as PE_LINK_84CNT_LUT30
0x2AA34 PE_LINK_84CNT_LUT513 — Protocol Encoder Link 84 Count LUT{PE_LINK_84CNT_LUT5}
  fields as PE_LINK_84CNT_LUT30
